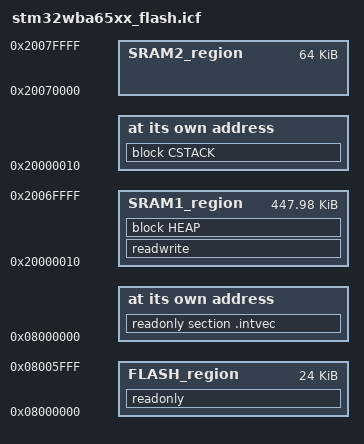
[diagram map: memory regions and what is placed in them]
/**********************************************************************************/
/**** Linker File (ICF)                                                        ****/
/**********************************************************************************/

/*-Series memory map-*/
define symbol __FLASH_BASE__              = 0x08000000;
define symbol __FLASH_TOP__               = 0x081FFFFF;
define symbol __SRAM1_BASE__              = 0x20000000;
define symbol __SRAM1_TOP__               = 0x2006FFFF;
define symbol __SRAM2_BASE__              = 0x20070000;
define symbol __SRAM2_TOP__               = 0x2007FFFF;

/*-Flash layout-*/
define symbol __region_FLASH_start__      = __FLASH_BASE__;
define symbol __region_FLASH_end__        = 0x08005FFF;

/*-RAM layout-*/
define symbol __region_SRAM1_start__      = __SRAM1_BASE__ + 0x10;
define symbol __region_SRAM1_end__        = __SRAM1_TOP__;
define symbol __region_SRAM2_start__      = __SRAM2_BASE__;
define symbol __region_SRAM2_end__        = __SRAM2_TOP__;

/*-Stack and heap-*/
define symbol __ICFEDIT_size_heap__   = 0x0000;
define symbol __ICFEDIT_size_cstack__ = 0x500;
define symbol __intvec_start__            = __region_FLASH_start__;

/*-Regions-*/
define memory mem with size = 4G;
define region FLASH_region      = mem:[from __region_FLASH_start__ to __region_FLASH_end__];
define region SRAM1_region      = mem:[from __region_SRAM1_start__ to __region_SRAM1_end__];
define region SRAM2_region      = mem:[from __region_SRAM2_start__ to __region_SRAM2_end__];
define region SRAM_region       = SRAM1_region | SRAM2_region;

/*-Blocks-*/
define block HEAP   with alignment = 8, size = __ICFEDIT_size_heap__   { };
define block CSTACK with alignment = 8, size = __ICFEDIT_size_cstack__ { };

/*-Initialization strategies-*/
initialize by copy { readwrite };
do not initialize  { section .noinit };

/*-Sections placements-*/
place at address mem:__intvec_start__ { readonly section .intvec };
place at address mem:__region_SRAM1_start__ { block CSTACK };
place in FLASH_region       { readonly };
place in SRAM1_region       { readwrite, block HEAP };
place in SRAM2_region       { };
place in SRAM_region        { };
